# pwrseq_es17 register map
Registers are access not given, no defined reset value unless marked. A register's access mark holds for its fields unless they carry their own. Offsets are from the block's base; lines under a group give offsets from that group; [hi:lo] are bit positions; {n}, {i} and the like mark numbered series; 'fields as' and 'values as' point back to an identical list; <NAME> marks a mode.

## Memory map
0x40006800 PWRSEQ size 0x400 — Power Sequencer / Low Power Control Register.

## PWRSEQ — Power Sequencer / Low Power Control Register.
Base 0x40006800
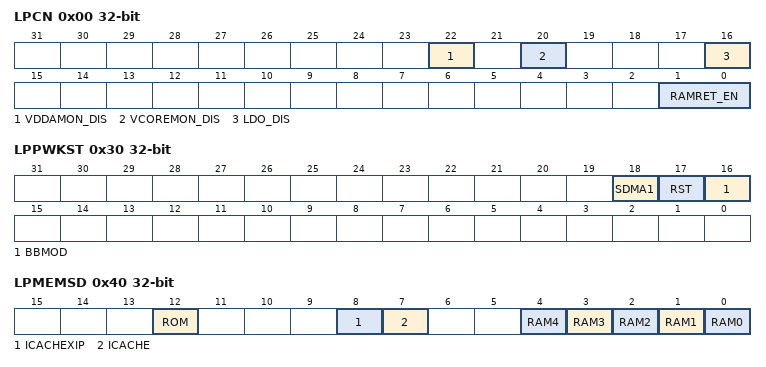
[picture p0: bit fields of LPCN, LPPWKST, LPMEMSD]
0x00 LPCN — Low Power Control Register.
  [22] VDDAMON_DIS — VDDA Monitor Disable. This bit controls the power monitor of the Analog Supply in all operating modes.
    0=en (Enable if Bandgap is ON (default)); 1=dis (Disabled.)
  [20] VCOREMON_DIS — Vcore Monitor Disable. This bit controls the power monitor on the VCore supply in all operating modes.
    0=en (Enable if Bandgap is ON (default)); 1=dis (Disabled.)
  [16] LDO_DIS — LDO Disabled
  [1:0] RAMRET_EN — System RAM retention in BACKUP mode. These two bits are used in conjuction with RREGEN bit.
0x04 LPWKST0 — Low Power I/O Wakeup Status Register 0. This register indicates the low power wakeup status for GPIO0.
  [15:0] ST — Wakeup IRQ flags (write ones to clear). One or more of these bits will be set when the corresponding dedicated GPIO pin (s) transition (s) from low to high or high to low. If GPIO wakeup source is selected, using PM.GPIOWKEN register, and the corresponding bit is also selected in LPWKEN register, an interrupt will be gnerated to wake up the CPU from a low power mode.
0x08 LPWKEN0 — Low Power I/O Wakeup Enable Register 0. This register enables low power wakeup functionality for GPIO0.
  [15:0] EN — Enable wakeup. These bits allow wakeup from the corresponding GPIO pin (s) on transition (s) from low to high or high to low when PM.GPIOWKEN is set. Wakeup status is indicated in PPWKST register.
0x0C LPWKST1 — Low Power I/O Wakeup Status Register 1. This register indicates the low power wakeup status for GPIO1.
  [10:0] ST — Wakeup IRQ flags (write ones to clear). One or more of these bits will be set when the corresponding dedicated GPIO pin (s) transition (s) from low to high or high to low. If GPIO wakeup source is selected, using PM.GPIOWKEN register, and the corresponding bit is also selected in LPWKEN register, an interrupt will be gnerated to wake up the CPU from a low power mode.
0x10 LPWKEN1 — Low Power I/O Wakeup Enable Register 1. This register enables low power wakeup functionality for GPIO1.
  [10:0] EN — Enable wakeup. These bits allow wakeup from the corresponding GPIO pin (s) on transition (s) from low to high or high to low when PM.GPIOWKEN is set. Wakeup status is indicated in PPWKST register.
0x30 LPPWKST — Low Power Peripheral Wakeup Status Register.
  [18] SDMA1 — Smart DMA (1) Detect Wakeup Flag (write one to clear). This bit will be set when the SDMA IRQ transitions from low to high or high to low
  [17] RST — Reset Detect Wakeup Flag (write one to clear). This bit will be set when the external reset causes wakeup
  [16] BBMOD — Battery Back Wakeup Flag (write one to clear). This bit will be set when exiting Battery Backup Mode.
0x40 LPMEMSD — Low Power Memory Shutdown Control.
  [all] fields
    0=Normal Operating Mode; 1=Shutdown Mode
  [12] ROM — ROM Shut Down.
  [8] ICACHEXIP — XiP Instruction Cache RAM Shut Down.
  [7] ICACHE — Instruction Cache RAM Shut Down.
  [n] RAM{n} (n=0..4) — System RAM block {n} Shut Down.
0x48 GP0 — Back Up General Purpose Register 0
0x4C GP1 — Back Up General Purpose Register 1
